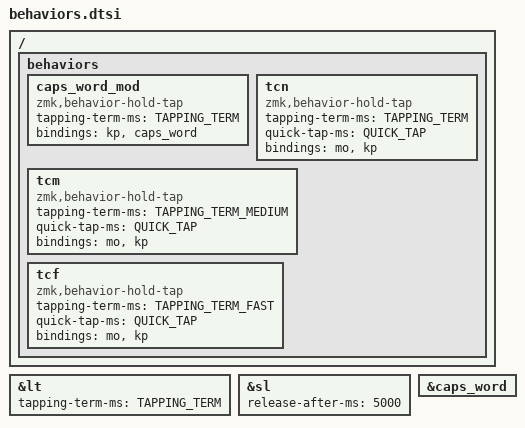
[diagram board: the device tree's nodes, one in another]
&lt {
    tapping-term-ms = <TAPPING_TERM>;
};

&sl {
    release-after-ms = <5000>;
};

&caps_word {
    /delete-property/ ignore-modifiers;
};

// Caps word
ZMK_HOLD_TAP(caps_word_mod,
   tapping-term-ms = <TAPPING_TERM>;
   bindings = <&kp>, <&caps_word>;
)
#define CAPS_WORD(MOD) &caps_word_mod MOD 0

// Thumb cluster tapping
ZMK_HOLD_TAP(tcn,
   tapping-term-ms = <TAPPING_TERM>;
   quick-tap-ms = <QUICK_TAP>;
   bindings = <&mo>, <&kp>;
)

ZMK_HOLD_TAP(tcm,
   tapping-term-ms = <TAPPING_TERM_MEDIUM>;
   quick-tap-ms = <QUICK_TAP>;
   bindings = <&mo>, <&kp>;
)

ZMK_HOLD_TAP(tcf,
   tapping-term-ms = <TAPPING_TERM_FAST>;
   quick-tap-ms = <QUICK_TAP>;
   bindings = <&mo>, <&kp>;
)

